# nRF7140_graphics register map
Vendor: Nordic Semiconductor; Series: nRF71; File version: 1
CPU: CM33 r0p4, little endian, MPU, FPU, 3 interrupt priority bits, 480 interrupts
Registers are 32-bit, read-write, reset 0x0 unless marked. A register's access mark holds for its fields unless they carry their own. Offsets are from the block's base; [hi:lo] are bit positions; lines under a group give offsets from that group; {n}, {i} and the like mark numbered series; 'fields as' and 'values as' point back to an identical list.

## GLOBAL_SAADC_NS — Analog to Digital Converter 0
Base 0x4F982000
Same registers: GLOBAL_SAADC_S 0x5F982000
0x00 TASKS_SAMPLE wo — Take one ADC sample, if scan is enabled all channels are sampled
  [0] TASKS_SAMPLE
    1=Trigger task
0x04 TASKS_CALIBRATEOFFSET wo — Starts offset auto-calibration
  [0] TASKS_CALIBRATEOFFSET
    1=Trigger task
0x08 TASKS_CALIBRATEGAIN wo — Starts gain auto-calibration
  [0] TASKS_CALIBRATEGAIN
    1=Trigger task
0x0C TASKS_DMA group — Peripheral tasks.
  0x00 START wo — Starts operation using easyDMA to load the values. See peripheral description for operation using easyDMA.
    [0] START
      1=Trigger task
  0x04 STOP wo — Stops operation using easyDMA. This does not trigger an END event. After a STOP task, the easyDMA (channel) will also enter its lowest required power level.
    [0] STOP
      1=Trigger task
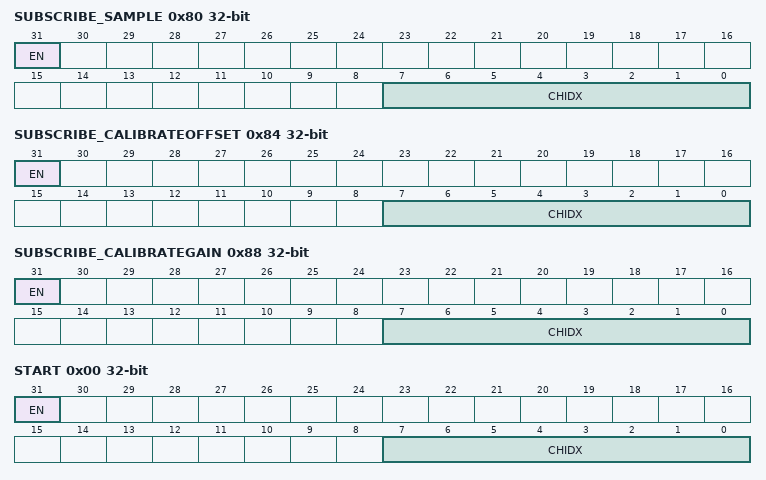
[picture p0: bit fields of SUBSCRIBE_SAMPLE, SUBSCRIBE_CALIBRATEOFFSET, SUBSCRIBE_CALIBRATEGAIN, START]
0x80 SUBSCRIBE_SAMPLE — Subscribe configuration for task SAMPLE
  [31] EN
    0=Disabled (Disable subscription); 1=Enabled (Enable subscription)
  [7:0] CHIDX — DPPI channel that task SAMPLE will subscribe to
0x84 SUBSCRIBE_CALIBRATEOFFSET — Subscribe configuration for task CALIBRATEOFFSET
  [31] EN
    values as SUBSCRIBE_SAMPLE.EN
  [7:0] CHIDX — DPPI channel that task CALIBRATEOFFSET will subscribe to
0x88 SUBSCRIBE_CALIBRATEGAIN — Subscribe configuration for task CALIBRATEGAIN
  [31] EN
    values as SUBSCRIBE_SAMPLE.EN
  [7:0] CHIDX — DPPI channel that task CALIBRATEGAIN will subscribe to
0x8C SUBSCRIBE_DMA group — Subscribe configuration for tasks
  0x00 START — Subscribe configuration for task START
    [31] EN
      values as SUBSCRIBE_SAMPLE.EN
    [7:0] CHIDX — DPPI channel that task START will subscribe to
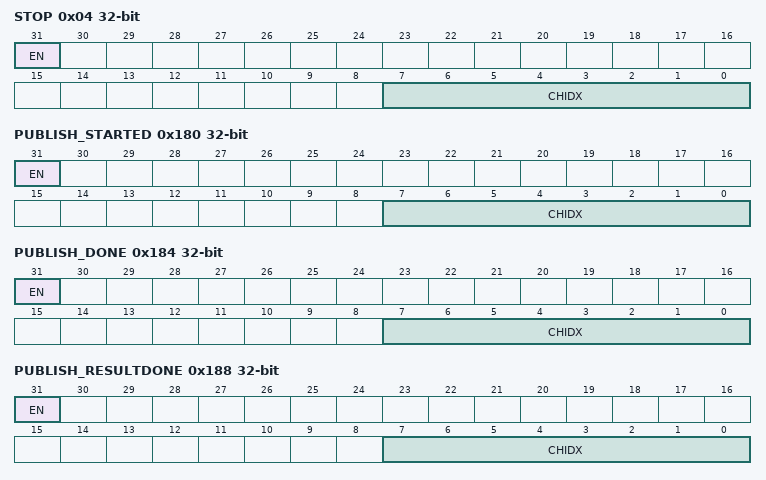
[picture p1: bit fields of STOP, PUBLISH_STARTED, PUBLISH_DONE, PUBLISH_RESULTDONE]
  0x04 STOP — Subscribe configuration for task STOP
    [31] EN
      values as SUBSCRIBE_SAMPLE.EN
    [7:0] CHIDX — DPPI channel that task STOP will subscribe to
0x100 EVENTS_STARTED — The ADC has started
  [0] EVENTS_STARTED
    0=NotGenerated (Event not generated); 1=Generated (Event generated)
0x104 EVENTS_DONE — A conversion task has been completed. Depending on the mode, multiple conversions might be needed for a result to be transferred to RAM.
  [0] EVENTS_DONE
    values as EVENTS_STARTED.EVENTS_STARTED
0x108 EVENTS_RESULTDONE — A result is ready to get transferred to RAM. Result is available in REGRESULT register
  [0] EVENTS_RESULTDONE
    values as EVENTS_STARTED.EVENTS_STARTED
0x10C EVENTS_CALIBRATEDONE — Calibration is complete
  [0] EVENTS_CALIBRATEDONE
    values as EVENTS_STARTED.EVENTS_STARTED
0x110 EVENTS_STOPPED — The ADC has stopped
  [0] EVENTS_STOPPED
    values as EVENTS_STARTED.EVENTS_STARTED
{0x114+8i} EVENTS_CH[{i}] (i=0..7) group — Peripheral events.
  0x00 LIMITH — Description cluster: Last results is equal or above CH[n].LIMIT.HIGH
    [0] LIMITH — Last results is equal or above CH[n].LIMIT.HIGH
      values as EVENTS_STARTED.EVENTS_STARTED
  0x04 LIMITL — Description cluster: Last results is equal or below CH[n].LIMIT.LOW
    [0] LIMITL — Last results is equal or below CH[n].LIMIT.LOW
      values as EVENTS_STARTED.EVENTS_STARTED
0x154 EVENTS_DMA group — Peripheral events.
  0x00 END — Generated after all MAXCNT bytes have been transferred Equivalent to eventDmaEnd[Channel]
    [0] END
      values as EVENTS_STARTED.EVENTS_STARTED
  0x04 READY — Generated when EasyDMA has buffered the .PTR and .MAXCNT registers for the channel, allowing them to be written to prepare for the next sequence.
    [0] READY
      values as EVENTS_STARTED.EVENTS_STARTED
  0x08 BUSERROR — An error occured during the bus transfer. This event is generated on an AHB / AXI error response.
    [0] BUSERROR
      values as EVENTS_STARTED.EVENTS_STARTED
0x180 PUBLISH_STARTED — Publish configuration for event STARTED
  [31] EN
    0=Disabled (Disable publishing); 1=Enabled (Enable publishing)
  [7:0] CHIDX — DPPI channel that event STARTED will publish to
0x184 PUBLISH_DONE — Publish configuration for event DONE
  [31] EN
    values as PUBLISH_STARTED.EN
  [7:0] CHIDX — DPPI channel that event DONE will publish to
0x188 PUBLISH_RESULTDONE — Publish configuration for event RESULTDONE
  [31] EN
    values as PUBLISH_STARTED.EN
  [7:0] CHIDX — DPPI channel that event RESULTDONE will publish to
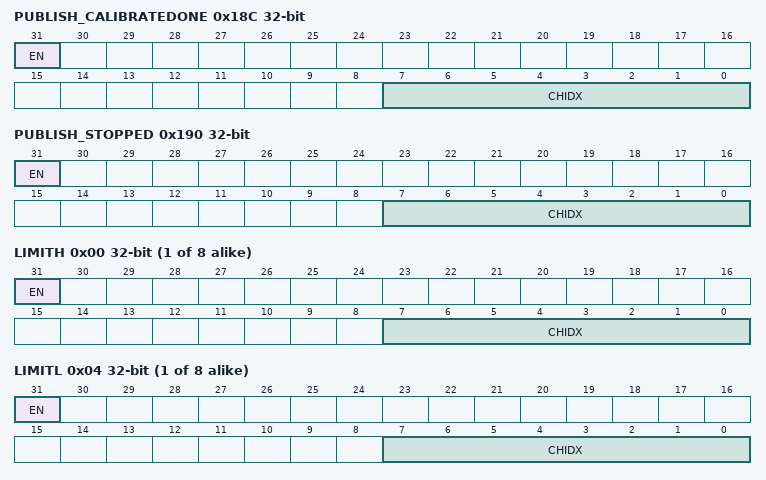
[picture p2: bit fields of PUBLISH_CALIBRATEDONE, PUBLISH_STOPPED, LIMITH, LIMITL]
0x18C PUBLISH_CALIBRATEDONE — Publish configuration for event CALIBRATEDONE
  [31] EN
    values as PUBLISH_STARTED.EN
  [7:0] CHIDX — DPPI channel that event CALIBRATEDONE will publish to
0x190 PUBLISH_STOPPED — Publish configuration for event STOPPED
  [31] EN
    values as PUBLISH_STARTED.EN
  [7:0] CHIDX — DPPI channel that event STOPPED will publish to
{0x194+8i} PUBLISH_CH[{i}] (i=0..7) group — Publish configuration for events
  0x00 LIMITH — Description cluster: Publish configuration for event CH[n].LIMITH
    [31] EN
      values as PUBLISH_STARTED.EN
    [7:0] CHIDX — DPPI channel that event CH[n].LIMITH will publish to
  0x04 LIMITL — Description cluster: Publish configuration for event CH[n].LIMITL
    [31] EN
      values as PUBLISH_STARTED.EN
    [7:0] CHIDX — DPPI channel that event CH[n].LIMITL will publish to
0x1D4 PUBLISH_DMA group — Publish configuration for events
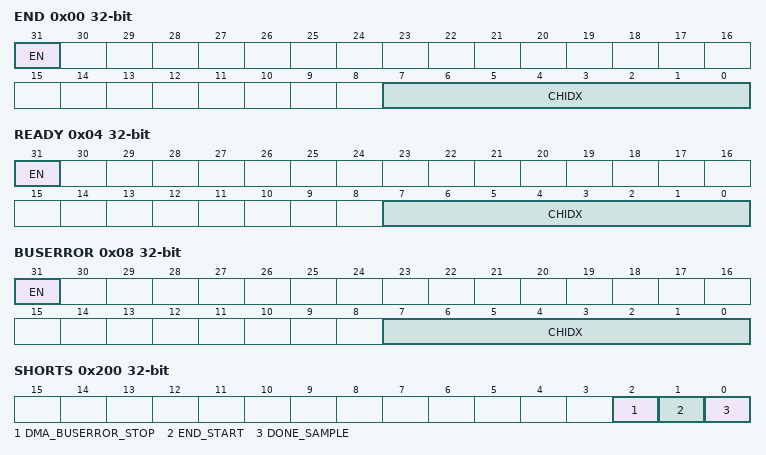
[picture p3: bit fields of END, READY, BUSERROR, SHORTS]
  0x00 END — Publish configuration for event END
    [31] EN
      values as PUBLISH_STARTED.EN
    [7:0] CHIDX — DPPI channel that event END will publish to
  0x04 READY — Publish configuration for event READY
    [31] EN
      values as PUBLISH_STARTED.EN
    [7:0] CHIDX — DPPI channel that event READY will publish to
  0x08 BUSERROR — Publish configuration for event BUSERROR
    [31] EN
      values as PUBLISH_STARTED.EN
    [7:0] CHIDX — DPPI channel that event BUSERROR will publish to
0x200 SHORTS — Shortcuts between local events and tasks
  [all] fields
    0=Disabled (Disable shortcut); 1=Enabled (Enable shortcut)
  [2] DMA_BUSERROR_STOP — Shortcut between event DMA.BUSERROR and task STOP
  [1] END_START — Shortcut between event END and task START
  [0] DONE_SAMPLE — Shortcut between event DONE and task SAMPLE
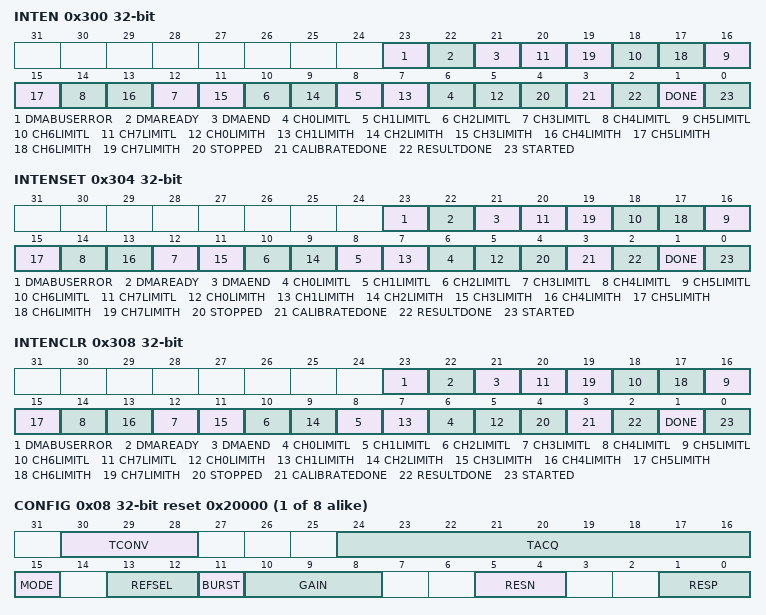
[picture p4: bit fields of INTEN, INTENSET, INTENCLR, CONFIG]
0x300 INTEN — Enable or disable interrupt
  [all] fields
    0=Disabled; 1=Enabled
  [23] DMABUSERROR — Enable or disable interrupt for event DMABUSERROR
  [22] DMAREADY — Enable or disable interrupt for event DMAREADY
  [21] DMAEND — Enable or disable interrupt for event DMAEND
  [2n+6] CH{n}LIMITL (n=0..7) — Enable or disable interrupt for event CH{n}LIMITL
  [2n+5] CH{n}LIMITH (n=0..7) — Enable or disable interrupt for event CH{n}LIMITH
  [4] STOPPED — Enable or disable interrupt for event STOPPED
  [3] CALIBRATEDONE — Enable or disable interrupt for event CALIBRATEDONE
  [2] RESULTDONE — Enable or disable interrupt for event RESULTDONE
  [1] DONE — Enable or disable interrupt for event DONE
  [0] STARTED — Enable or disable interrupt for event STARTED
0x304 INTENSET — Enable interrupt
  [all] fields
    on read: 0=Disabled (Read: Disabled); 1=Enabled (Read: Enabled) | on write: 1=Set (Enable)
  [23] DMABUSERROR — Write '1' to enable interrupt for event DMABUSERROR
  [22] DMAREADY — Write '1' to enable interrupt for event DMAREADY
  [21] DMAEND — Write '1' to enable interrupt for event DMAEND
  [2n+6] CH{n}LIMITL (n=0..7) — Write '1' to enable interrupt for event CH{n}LIMITL
  [2n+5] CH{n}LIMITH (n=0..7) — Write '1' to enable interrupt for event CH{n}LIMITH
  [4] STOPPED — Write '1' to enable interrupt for event STOPPED
  [3] CALIBRATEDONE — Write '1' to enable interrupt for event CALIBRATEDONE
  [2] RESULTDONE — Write '1' to enable interrupt for event RESULTDONE
  [1] DONE — Write '1' to enable interrupt for event DONE
  [0] STARTED — Write '1' to enable interrupt for event STARTED
0x308 INTENCLR — Disable interrupt
  [all] fields
    on read: 0=Disabled (Read: Disabled); 1=Enabled (Read: Enabled) | on write: 1=Clear (Disable)
  [23] DMABUSERROR — Write '1' to disable interrupt for event DMABUSERROR
  [22] DMAREADY — Write '1' to disable interrupt for event DMAREADY
  [21] DMAEND — Write '1' to disable interrupt for event DMAEND
  [2n+6] CH{n}LIMITL (n=0..7) — Write '1' to disable interrupt for event CH{n}LIMITL
  [2n+5] CH{n}LIMITH (n=0..7) — Write '1' to disable interrupt for event CH{n}LIMITH
  [4] STOPPED — Write '1' to disable interrupt for event STOPPED
  [3] CALIBRATEDONE — Write '1' to disable interrupt for event CALIBRATEDONE
  [2] RESULTDONE — Write '1' to disable interrupt for event RESULTDONE
  [1] DONE — Write '1' to disable interrupt for event DONE
  [0] STARTED — Write '1' to disable interrupt for event STARTED
0x400 STATUS ro
  [0] STATUS
    0=Ready (ADC is ready. No on-going conversion.); 1=Busy (ADC is busy. Single conversion in progress.)
0x404 PCRMSTATUS ro
  [0] ACK — PCRM Ack Status for the PCRM clean power request
    0=NoAck (Ack not received.); 1=Ack (Ack received.)
0x440 TRIM group — Unspecified
  {0x0+4j} LINCALCOEFF[{j}] (j=0..5) — Description collection: Linearity calibration coefficient
    [15:0] VAL — value
0x500 ENABLE — Enable or disable ADC
  [0] ENABLE
    0=Disabled (Disable ADC); 1=Enabled (Enable ADC)
{0x510+0x10*i} CH[{i}] (i=0..7) group — Unspecified
  0x00 PSELP — Description cluster: Input positive pin selection for CH[n]
    [4:0] PSELP — Analog positive input channel
      0=NC (Not connected); {v}=AnalogInput{v-1} (AIN{v-1}) (v=1..8); 9=ATB2; 10=ATB1; 11=VDDTest0 (Connected to VDD_AO_1V8); 12=VDDTest1 (Connected to VDD_AO_0V8); 13=VDDTest2 (Connected to VDD_IO_1V2); 14=Spare (Reserved for future use); 15=AVSS; 16=SELREF (Selected reference, voltage determined by PADC_REFSEL); {v}=AnalogInput{v-9} (AIN{v-9}) (v=17..22)
  0x04 PSELN — Description cluster: Input negative pin selection for CH[n]
    [4:0] PSELN — Analog negative input, enables differential channel
      0=NC (Not connected); {v}=AnalogInput{v-1} (AIN{v-1}) (v=1..8); 9=ATB0; 10=ATB1; 11=VDDTest3 (Connected to VDD_1V0); 12=VDDTest4 (Reserved for VDD_PPA_1V6 (Halti only)); 13=VDDTest5 (Reserved for VDD_AO_5V0); 14=Spare (Reserved for future use); 15=AVSS; 16=SELREF (Selected reference, voltage determined by PADC_REFSEL); {v}=AnalogInput{v-9} (AIN{v-9}) (v=17..22)
  0x08 CONFIG reset 0x20000 — Description cluster: Input configuration for CH[n]
    [30:28] TCONV — Conversion time. Resulting conversion time is ((TCONV+1) x 250 ns)
    [24:16] TACQ — Acquisition time, the time the ADC uses to sample the input voltage. Resulting acquistion time is ((TACQ+1) x 125 ns)
    [15] MODE — Enable differential mode
      0=SE (Single ended, PSELN will be ignored, negative input to ADC shorted to GND); 1=Differential
    [13:12] REFSEL — Reference control
      0=Internal reference (1.024 V); 1=External reference given at PADC_EXT_REF_1V2; 2=IBPSR4UPADC (Reference generated by IBPSR_4U_PADC)
    [11] BURST — Enable burst mode
      0=Disabled (Burst mode is disabled (normal operation)); 1=Enabled (Burst mode is enabled. SAADC takes 2^OVERSAMPLE number of samples as fast as it can, and sends the average to Data RAM.)
    [10:8] GAIN — Gain control
      0=Gain2_3 (2/3); 1=1; 2=2; 3=4
    [5:4] RESN — Negative channel resistor control
      0=Bypass resistor ladder; 1=Pull-down to GND; 2=Pull-up to VDD_AO_1V8; 3=VDDAO1V8div2 (Set input at VDD_AO_1V8/2)
    [1:0] RESP — Positive channel resistor control
      values as RESN
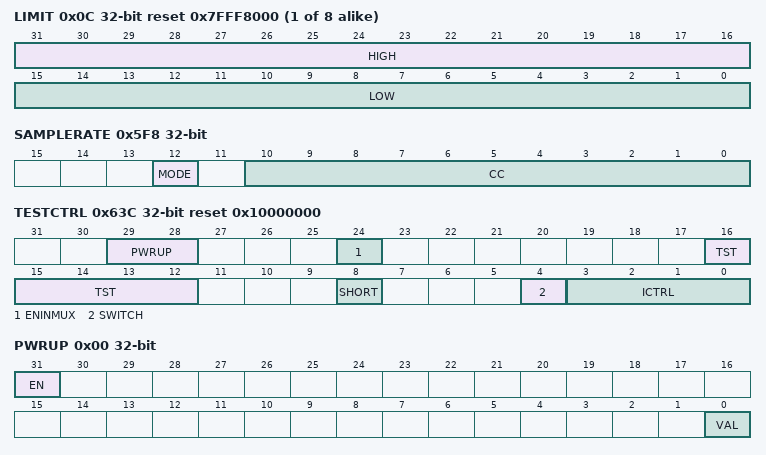
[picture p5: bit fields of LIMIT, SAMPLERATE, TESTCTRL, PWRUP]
  0x0C LIMIT reset 0x7FFF8000 — Description cluster: High/low limits for event monitoring a channel
    [31:16] HIGH — High level limit
    [15:0] LOW — Low level limit
0x5EC REGRESULT ro — Last conversion result
  [31:0] REGRESULT — Result of the previous ADC conversion
0x5F0 RESOLUTION reset 0x1 — Resolution configuration
  [2:0] VAL — Set the resolution
    0=8bit; 1=10bit; 2=12bit; 3=14bit; 4=16bit
0x5F4 OVERSAMPLE — Oversampling configuration. OVERSAMPLE should not be combined with SCAN. The RESOLUTION is applied before averaging, thus for high OVERSAMPLE a higher RESOLUTION should be used.
  [3:0] OVERSAMPLE — Oversample control
    0=Bypass oversampling; 1=Over2x (Oversample 2x); 2=Over4x (Oversample 4x); 3=Over8x (Oversample 8x); 4=Over16x (Oversample 16x); 5=Over32x (Oversample 32x); 6=Over64x (Oversample 64x); 7=Over128x (Oversample 128x); 8=Over256x (Oversample 256x); 9=Over512x (Oversample 512x); 10=Over1024x (Oversample 1024x); 11=Over2048x (Oversample 2048x); 12=Over4096x (Oversample 4096x)
0x5F8 SAMPLERATE — Controls normal or continuous sample rate
  [12] MODE — Select mode for sample rate control
    0=Task (Rate is controlled from SAMPLE task); 1=Timers (Rate is controlled from local timer (use CC to control the rate))
  [10:0] CC — Capture and compare value. Sample rate is 16 MHz/CC
0x5FC PCRMREQ — PCRM request for clean power
  [0] REQ — Request
    0=Disabled (Request disabled.); 1=Enabled (Request enabled.)
0x63C TESTCTRL reset 0x10000000 — Control signals used during test of ADC
  [29:28] PWRUP — Power-up time
    0=6us; 1=10us; 2=15us; 3=20us
  [24] ENINMUX — Will enable the input mux in the ADC, so the resistor strings can be connected even when the analog core is powered down. See design description for coding
  [16:12] TST — Test bus for ADC core. See design description for coding
  [8] SHORT — Short input. Used to measure offset of ADC. See design description for coding
  [4] SWITCH — Swap positive and negative input. See design description for coding
  [3:0] ICTRL — Current control. See design description for coding
0x640 CALOFFSET — Calibration control for offset error
  [5:0] CALOFFSET — Sign-magnitude coding
    0=Default setting; 31=MaxPos (Maximum positive offset); 32=MaxNeg (maximum negative offset)
0x644 CALGAIN — Calibration control for gain error
  [6:0] CALGAIN — Offset binary coding
    0=Default gain, for +1/2 input (assume full-scale = +-1) the output will be 1024; 63=High gain setting; 64=Low (Low gain setting)
0x648 CALVREF — Calibration control for reference voltage
  [6:0] CALVREF — Offset binary coding
    0=Default vref, in typical corner VREF=1.2V; 63=High (Low output code (high reference voltage)); 64=Low (High output code (low reference voltage))
0x64C CALIREF — Calibration control for reference current
  [3:0] CALIREF — Calibration control for reference current. See design description for coding
0x650 CALVREFTC — Calibration code for reference temperature coefficient
  [2:0] CALVREFTC — Calibration code for reference temperature coefficient. See design description for coding
0x654 NOISESHAPE — Enable noise shaping
  [1:0] NOISESHAPE
    0=Disable (Oversampling based on accumulate and average. Used in high-speed mode (10-bit)); 1=Enable (Oversampling based on noise shaping. Used in high-accuracy modes (12-bit and 14-bit))
0x680 OVERRIDE group — Unspecified
  0x00 PWRUP — Override the PWRUP signal to the analog module
    [31] EN — Enable the override
      0=Disabled (Override is disabled); 1=Enabled (Override is enabled)
    [0] VAL — Override value for the signal
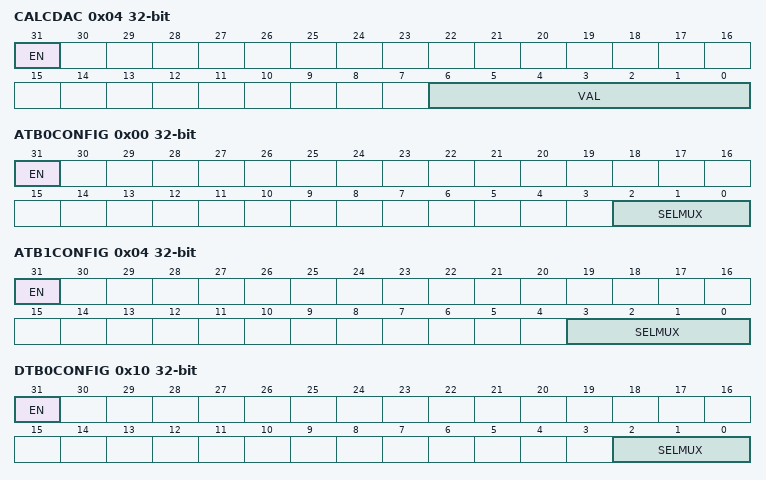
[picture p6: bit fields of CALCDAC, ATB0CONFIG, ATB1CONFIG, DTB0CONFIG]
  0x04 CALCDAC — Override the CAL_CDAC signal to the analog module
    [31] EN — Enable the override
      values as OVERRIDE.PWRUP.EN
    [6:0] VAL — Override value for the signal
0x700 DMA group — Unspecified
  0x00 ENABLE — Register doesn't do anything. Can be written and read, but has no functionality attached.
    [0] ENABLE
      0=Disabled; 1=Enabled
  0x04 PTR — RAM buffer start address
    [31:0] PTR — RAM buffer start address for this EasyDMA channel. This address is a word aligned Data RAM address.
  0x08 MAXCNT — Maximum number of bytes in receive buffer
    [15:0] MAXCNT
  0x0C AMOUNT ro — Number of bytes transferred in the last transaction, updated after the END event.
    [15:0] AMOUNT — Number of bytes transferred in the last transaction. In case of NACK error, includes the NACK'ed byte.
  0x1C TERMINATEONBUSERROR — Terminate the transaction if a BUSERROR event is detected.
    [0] ENABLE
      0=Disabled; 1=Enabled
  0x20 BUSERRORADDRESS — Address of transaction that generated the last BUSERROR event.
    [31:0] ADDRESS
0x800 DFT group — Unspecified
  0x00 ATB0CONFIG — Analog Test Bus 0 (ATB0) configuration
    [31] EN — Enable the analog test bus
      0=Disabled (Analog test bus is disabled); 1=Enabled (Analog test bus is enabled)
    [2:0] SELMUX — Select multiplexer for ATB0
      0=INMUX (ATB0 connected to PADC_INMUX, available on PADC_IN); 1=VREF (ATB0 connected to VREF); 2=VREFBUFF (ATB0 connected to VREF_BUFF); 3=VREFIBPSR10U (ATB0 connected to ATB_PADC_VREF_IBPSR_10U for current measurement); 4=VREFIBPS3U (ATB0 connected to ATB_PADC_VREF_IBPS_3U); 5=Spare0 (Spare pin); 6=Spare1 (Spare pin); 7=Spare2 (Spare pin)
  0x04 ATB1CONFIG — Analog Test Bus 1 (ATB1) configuration
    [31] EN — Enable the analog test bus
      values as DFT.ATB0CONFIG.EN
    [3:0] SELMUX — Select multiplexer for ATB1
      0=INMUX (ATB1 connected to PADC_INMUX, available on both PADC_IP and PADC_IN); 1=VREFviaATBBUF (ATB1 connected to VREF via ATBBUF); 2=VREFBUFFviaATBUF (ATB1 connected to VREF_BUFF via ATBUF); 3=LDO (ATB1 connected to PADC_LDO resistive divider to measure 1.5V/2 via ATBUF); 4=VREFIBPS3U (SATB1 connected to ATB_PADC_VREF_IBPS_3U); 5=Spare0 (Spare pin); 6=Spare1 (Spare pin); 7=Spare2 (Spare pin)
  0x08 ATB2CONFIG — Analog Test Bus 2 (ATB2) configuration
    [31] EN — Enable the analog test bus
      0=Disabled (Analog test bus is disabled); 1=Enabled (Analog test bus is enabled and connected to PADC_INMUX available on PADC_IP)
  0x10 DTB0CONFIG — Digital Test Bus 0 (DTB0) configuration
    [31] EN — Enable the digital test bus
      0=Disabled (Digital test bus is disabled); 1=Enabled (Digital test bus is enabled)
    [2:0] SELMUX — Select multiplexer for DTB0
      0=READY (READY_PADC_AO_0V8); 1=READYVREF (READY_PADC_VREF_AO_0V8); 2=SETTLED (SETTLED_VDD_INT_AO_0V8); 3=INTCONVERT (INT_CONVERT_0V8); 4=INTDONE (INT_DONE_0V8); 5=INTAMPLFIY (INT_AMPLFIY_0V8); 6=Spare0 (Spare pin); 7=Spare1 (Spare pin)
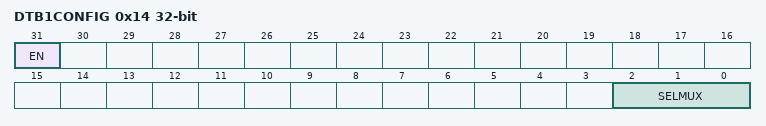
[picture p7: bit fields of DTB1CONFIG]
  0x14 DTB1CONFIG — Digital Test Bus 1 (DTB1) configuration
    [31] EN — Enable the digital test bus
      values as DFT.DTB0CONFIG.EN
    [2:0] SELMUX — Select multiplexer for DTB1
      0=INTIDLE (INT_IDLE_0V8); 1=INTSAMPLE (INT_SAMPLE_0V8); 2=INTAMPLFIY (INT_AMPLFIY_0V8); 3=INTCONVERT (INT_CONVERT_0V8); 4=INTDONE (INT_DONE_0V8); 5=ENNSERRFEEDBACK (EN_NS_ERR_FEEDBACK_0V8); 6=Spare0 (Spare pin); 7=Spare1 (Spare pin)
